# MK30D7 register map
File version: 1.6
Registers are 32-bit, read-write, reset 0x0 unless marked. A register's access mark holds for its fields unless they carry their own. Offsets are from the block's base; [hi:lo] are bit positions; {n}, {i} and the like mark numbered series; 'fields as' and 'values as' point back to an identical list.

## LCD — Segment Liquid Crystal Display
Base 0x400BE000; register names take the prefix LCD_
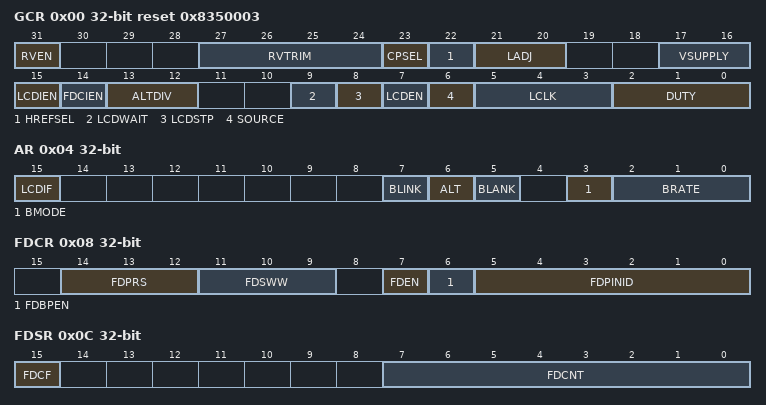
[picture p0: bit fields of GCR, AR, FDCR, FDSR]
0x00 GCR access per field reset 0x8350003 — LCD general control register
  [31] RVEN rw — Regulated voltage enable
    0=Regulated voltage disabled; 1=Regulated voltage enabled
  [27:24] RVTRIM rw — Regulated voltage trim
  [23] CPSEL rw — Charge pump or resistor bias select
    0=LCD charge pump is disabled. Resistor network selected. (The internal 1/3-bias is forced.); 1=LCD charge pump is selected. Resistor network disabled. (The internal 1/3-bias is forced.)
  [22] HREFSEL rw — High reference select
    0=Divide input, VIREG = 1.0 V for 3 V glass; 1=Do not divide the input, VIREG = 1.67 V for 5 V glass
  [21:20] LADJ rw — Load adjust
  [17:16] VSUPPLY rw — Voltage supply control
    0=Drive VLL2 internally from VDD; 1=Drive VLL3 internally from VDD; 3=Drive VLL3 externally from VDD or drive VLL1 internally from VIREG
  [15] LCDIEN rw — LCD frame frequency interrupt enable
    0=No interrupt request is generated by this event; 1=When LCDIF bit is set, this event causes an interrupt request
  [14] FDCIEN rw — LCD fault detection complete interrupt enable
    0=No interrupt request is generated by this event; 1=When a fault is detected and FDCF bit is set, this event causes an interrupt request
  [13:12] ALTDIV rw — LCD alternate clock divider
    0=Divide factor = 1 (No divide); 1=Divide factor = 8
  [9] LCDWAIT rw — LCD driver, charge pump, resistor bias network, and voltage regulator stop while in Wait mode.
    0=Allows the LCD driver, charge pump, resistor bias network, and voltage regulator to continue running during Wait mode; 1=Disables the LCD driver, charge pump, resistor bias network, and voltage regulator when MCU goes into Wait mode
  [8] LCDSTP rw — LCD driver, charge pump, resistor bias network, and voltage regulator while in Stop mode.
    0=Allows the LCD driver, charge pump, resistor bias network, and voltage regulator to continue running during Stop mode; 1=Disables the LCD driver, charge pump, resistor bias network, and voltage regulator when MCU goes into Stop mode
  [7] LCDEN rw — LCD driver enable
    0=All frontplane and backplane pins are disabled. The LCD controller system is also disabled, and all LCD waveform generation clocks are stopped. VLL3 is connected to VDD internally.; 1=LCD controller driver system is enabled, and frontplane and backplane waveforms are generated. All LCD pins, LCD_Pn, enabled using the LCD pin enable register, output an LCD driver waveform.The backplane pins output an LCD driver backplane waveform based on the settings of DUTY[2:0]. Charge pump or resistor bias is enabled.
  [6] SOURCE rw — LCD clock source select
    0=Selects the default clock as the LCD clock source; 1=Selects the alternate clock as the LCD clock source
  [5:3] LCLK rw — LCD clock prescaler
  [2:0] DUTY rw — LCD duty select
    0=Use 1 BP (1/1 duty cycle); 1=Use 2 BP (1/2 duty cycle); 2=Use 3 BP (1/3 duty cycle); 3=Use 4 BP (1/4 duty cycle). (Default); {v}=Use {v+1} BP (1/{v+1} duty cycle) (v=4..7)
0x04 AR access per field — LCD auxiliary register
  [15] LCDIF rw — LCD frame frequency interrupt flag
    0=Frame frequency interrupt condition has not occurred; 1=The start of LCD controller frame has occurred
  [7] BLINK rw — Blink command
    0=Disables blinking; 1=Starts blinking at blinking frequency specified by LCD blink rate calculation
  [6] ALT rw — Alternate display mode
    0=Normal display mode; 1=Alternate display mode
  [5] BLANK rw — Blank display mode
    0=Normal or alternate display mode; 1=Blank display mode
  [3] BMODE rw — Blink mode
    0=Display blank during the blink period; 1=Display alternate display during blink period (Ignored if duty is 5 or greater)
  [2:0] BRATE rw — Blink-rate configuration
0x08 FDCR access per field — LCD fault detect control register
  [14:12] FDPRS rw — Fault detect clock prescaler
    0=1/1 bus clock; 1=1/2 bus clock
  [11:9] FDSWW rw — Fault detect sample window width
    0=Sample window width is 4 sample clock cycles; 1=Sample window width is 8 sample clock cycles
  [7] FDEN rw — Fault detect enable
    0=Disable fault detection; 1=Enable fault detection
  [6] FDBPEN rw — Fault detect backplane enable
    0=Type of the selected pin under fault detect test is frontplane; 1=Type of the selected pin under fault detect test is backplane
  [5:0] FDPINID rw — Fault detect pin ID
    0=Fault detection for LCD_P0 pin; 1=Fault detection for LCD_P1 pin
0x0C FDSR access per field — LCD fault detect status register
  [15] FDCF rw — Fault detection complete flag
    0=Fault detection is not completed; 1=Fault detection is completed
  [7:0] FDCNT ro — Fault detect counter
    0=No "one" samples; 1=1 "one" samples
0x10 PEN{x} (x=L,H; step 0x4) — LCD pin enable register
  [31:0] PEN — LCD pin enable
    0=LCD operation disabled on LCD_Pn; 1=LCD operation enabled on LCD_Pn
0x18 BPEN{x} (x=L,H; step 0x4) — LCD backplane enable register
  [31:0] BPEN — Backplane enable
    0=Frontplane operation enabled on LCD_Pn; 1=Backplane operation enabled on LCD_Pn
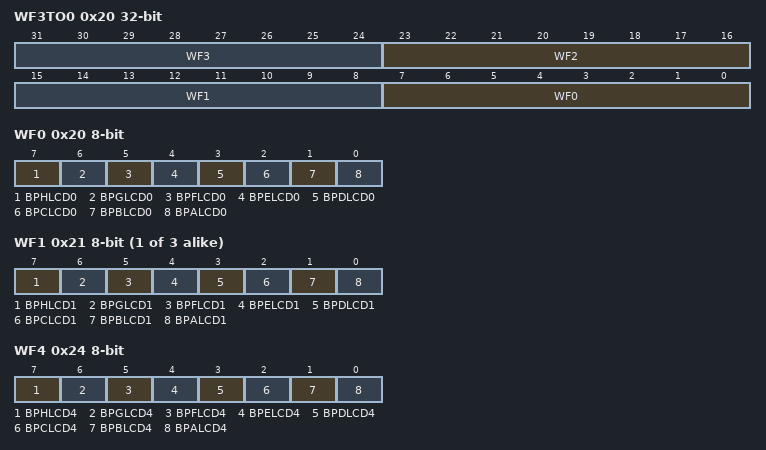
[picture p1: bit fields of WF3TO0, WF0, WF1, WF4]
0x20 WF3TO0 (LCD view) — LCD waveform register
  [8n+7:8n] WF{n} (n=0..3)
0x20 WF0 8-bit reset not defined (LCD view) — LCD Waveform Register 0.
  [7] BPHLCD0
    0=LCD segment off or LCD backplane inactive for phase H; 1=LCD segment on or LCD backplane active for phase H
  [6] BPGLCD0
    0=LCD segment off or LCD backplane inactive for phase G; 1=LCD segment on or LCD backplane active for phase G
  [5] BPFLCD0
    0=LCD segment off or LCD backplane inactive for phase F; 1=LCD segment on or LCD backplane active for phase F
  [4] BPELCD0
    0=LCD segment off or LCD backplane inactive for phase E; 1=LCD segment on or LCD backplane active for phase E
  [3] BPDLCD0
    0=LCD segment off or LCD backplane inactive for phase D; 1=LCD segment on or LCD backplane active for phase D
  [2] BPCLCD0
    0=LCD segment off or LCD backplane inactive for phase C; 1=LCD segment on or LCD backplane active for phase C
  [1] BPBLCD0
    0=LCD segment off or LCD backplane inactive for phase B; 1=LCD segment on or LCD backplane active for phase B
  [0] BPALCD0
    0=LCD segment off or LCD backplane inactive for phase A; 1=LCD segment on or LCD backplane active for phase A
{0x20+i} WF{i} 8-bit reset not defined (i=1..3) — LCD Waveform Register {i}.
  [7] BPHLCD{i}
    values as WF0.BPHLCD0
  [6] BPGLCD{i}
    values as WF0.BPGLCD0
  [5] BPFLCD{i}
    values as WF0.BPFLCD0
  [4] BPELCD{i}
    values as WF0.BPELCD0
  [3] BPDLCD{i}
    values as WF0.BPDLCD0
  [2] BPCLCD{i}
    values as WF0.BPCLCD0
  [1] BPBLCD{i}
    values as WF0.BPBLCD0
  [0] BPALCD{i}
    values as WF0.BPALCD0
0x24 WF4 8-bit reset not defined (LCD view) — LCD Waveform Register 4.
  [7] BPHLCD4
    values as WF0.BPHLCD0
  [6] BPGLCD4
    values as WF0.BPGLCD0
  [5] BPFLCD4
    values as WF0.BPFLCD0
  [4] BPELCD4
    values as WF0.BPELCD0
  [3] BPDLCD4
    values as WF0.BPDLCD0
  [2] BPCLCD4
    values as WF0.BPCLCD0
  [1] BPBLCD4
    values as WF0.BPBLCD0
  [0] BPALCD4
    values as WF0.BPALCD0
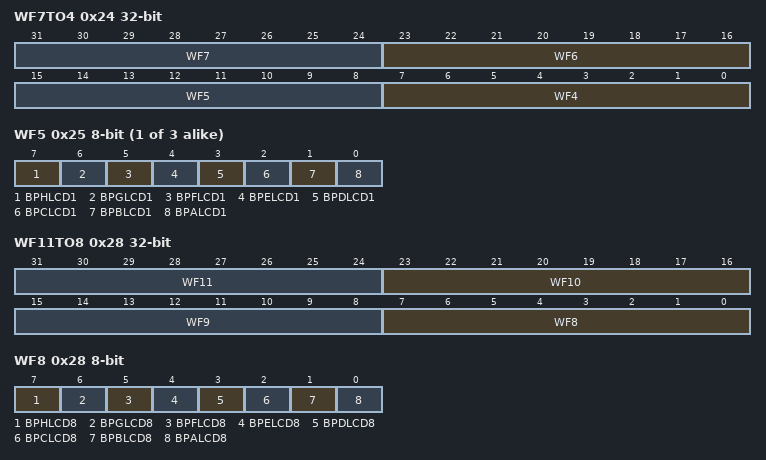
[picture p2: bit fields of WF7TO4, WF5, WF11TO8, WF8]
0x24 WF7TO4 (LCD view) — LCD waveform register
  [8n-25:8n-32] WF{n} (n=4..7)
{0x20+i} WF{i} 8-bit reset not defined (i=5..7) — LCD Waveform Register {i}.
  fields as WF1
0x28 WF11TO8 (LCD view) — LCD waveform register
  [8n-57:8n-64] WF{n} (n=8..11)
0x28 WF8 8-bit reset not defined (LCD view) — LCD Waveform Register 8.
  [7] BPHLCD8
    values as WF0.BPHLCD0
  [6] BPGLCD8
    values as WF0.BPGLCD0
  [5] BPFLCD8
    values as WF0.BPFLCD0
  [4] BPELCD8
    values as WF0.BPELCD0
  [3] BPDLCD8
    values as WF0.BPDLCD0
  [2] BPCLCD8
    values as WF0.BPCLCD0
  [1] BPBLCD8
    values as WF0.BPBLCD0
  [0] BPALCD8
    values as WF0.BPALCD0
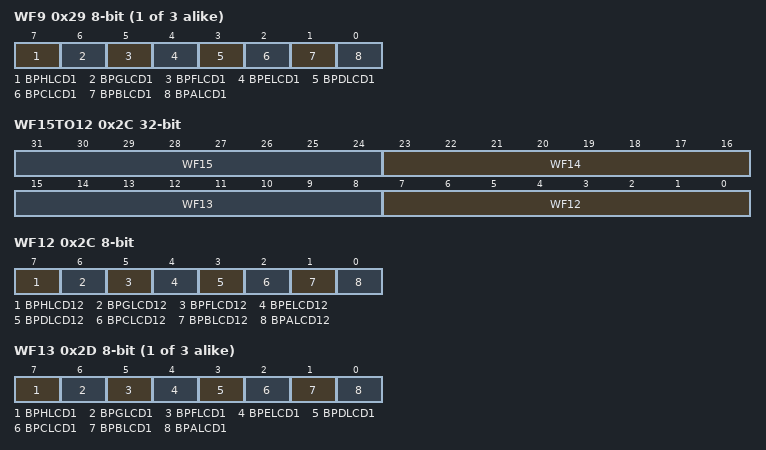
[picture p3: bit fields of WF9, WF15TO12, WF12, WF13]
{0x20+i} WF{i} 8-bit reset not defined (i=9..11) — LCD Waveform Register {i}.
  fields as WF1
0x2C WF15TO12 (LCD view) — LCD waveform register
  [8n-89:8n-96] WF{n} (n=12..15)
0x2C WF12 8-bit reset not defined (LCD view) — LCD Waveform Register 12.
  [7] BPHLCD12
    values as WF0.BPHLCD0
  [6] BPGLCD12
    values as WF0.BPGLCD0
  [5] BPFLCD12
    values as WF0.BPFLCD0
  [4] BPELCD12
    values as WF0.BPELCD0
  [3] BPDLCD12
    values as WF0.BPDLCD0
  [2] BPCLCD12
    values as WF0.BPCLCD0
  [1] BPBLCD12
    values as WF0.BPBLCD0
  [0] BPALCD12
    values as WF0.BPALCD0
{0x20+i} WF{i} 8-bit reset not defined (i=13..15) — LCD Waveform Register {i}.
  fields as WF1
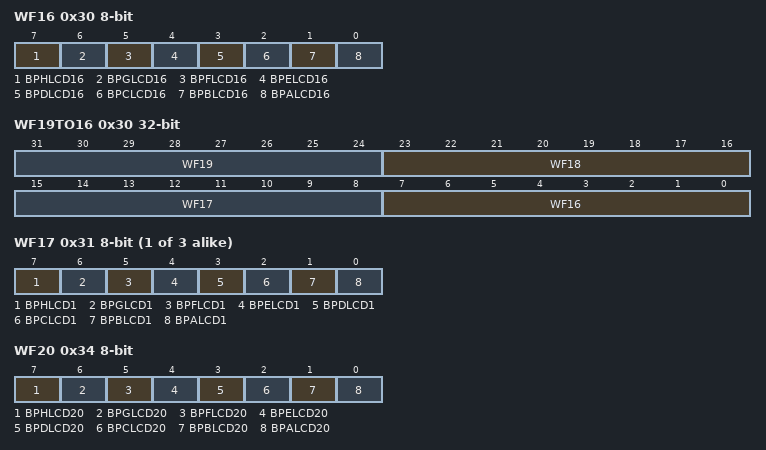
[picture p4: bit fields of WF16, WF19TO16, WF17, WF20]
0x30 WF16 8-bit reset not defined (LCD view) — LCD Waveform Register 16.
  [7] BPHLCD16
    values as WF0.BPHLCD0
  [6] BPGLCD16
    values as WF0.BPGLCD0
  [5] BPFLCD16
    values as WF0.BPFLCD0
  [4] BPELCD16
    values as WF0.BPELCD0
  [3] BPDLCD16
    values as WF0.BPDLCD0
  [2] BPCLCD16
    values as WF0.BPCLCD0
  [1] BPBLCD16
    values as WF0.BPBLCD0
  [0] BPALCD16
    values as WF0.BPALCD0
0x30 WF19TO16 (LCD view) — LCD waveform register
  [8n-121:8n-128] WF{n} (n=16..19)
{0x20+i} WF{i} 8-bit reset not defined (i=17..19) — LCD Waveform Register {i}.
  fields as WF1
0x34 WF20 8-bit reset not defined (LCD view) — LCD Waveform Register 20.
  [7] BPHLCD20
    values as WF0.BPHLCD0
  [6] BPGLCD20
    values as WF0.BPGLCD0
  [5] BPFLCD20
    values as WF0.BPFLCD0
  [4] BPELCD20
    values as WF0.BPELCD0
  [3] BPDLCD20
    values as WF0.BPDLCD0
  [2] BPCLCD20
    values as WF0.BPCLCD0
  [1] BPBLCD20
    values as WF0.BPBLCD0
  [0] BPALCD20
    values as WF0.BPALCD0
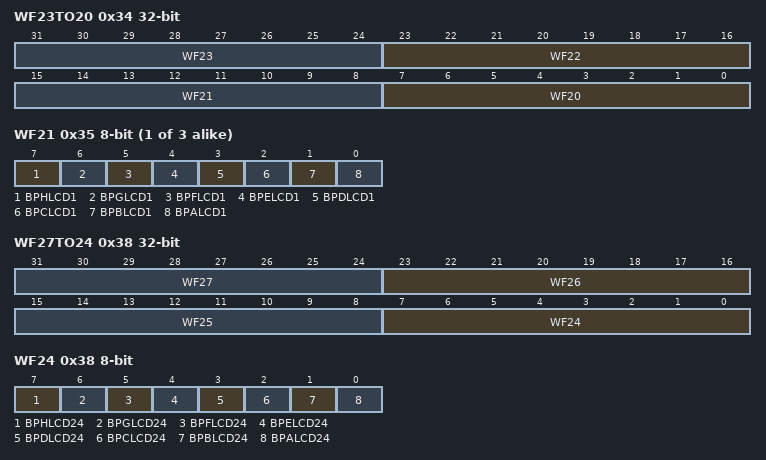
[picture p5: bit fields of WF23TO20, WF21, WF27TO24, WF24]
0x34 WF23TO20 (LCD view) — LCD waveform register
  [8n-153:8n-160] WF{n} (n=20..23)
{0x20+i} WF{i} 8-bit reset not defined (i=21..23) — LCD Waveform Register {i}.
  fields as WF1
0x38 WF27TO24 (LCD view) — LCD waveform register
  [8n-185:8n-192] WF{n} (n=24..27)
0x38 WF24 8-bit reset not defined (LCD view) — LCD Waveform Register 24.
  [7] BPHLCD24
    values as WF0.BPHLCD0
  [6] BPGLCD24
    values as WF0.BPGLCD0
  [5] BPFLCD24
    values as WF0.BPFLCD0
  [4] BPELCD24
    values as WF0.BPELCD0
  [3] BPDLCD24
    values as WF0.BPDLCD0
  [2] BPCLCD24
    values as WF0.BPCLCD0
  [1] BPBLCD24
    values as WF0.BPBLCD0
  [0] BPALCD24
    values as WF0.BPALCD0
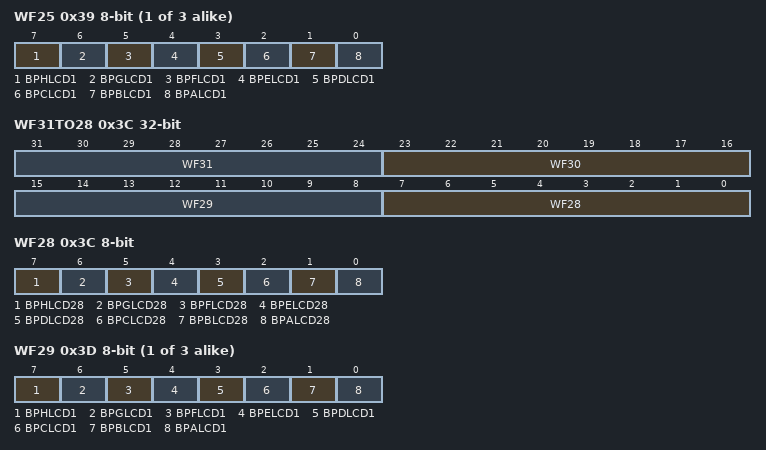
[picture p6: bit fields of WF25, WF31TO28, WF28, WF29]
{0x20+i} WF{i} 8-bit reset not defined (i=25..27) — LCD Waveform Register {i}.
  fields as WF1
0x3C WF31TO28 (LCD view) — LCD waveform register
  [8n-217:8n-224] WF{n} (n=28..31)
0x3C WF28 8-bit reset not defined (LCD view) — LCD Waveform Register 28.
  [7] BPHLCD28
    values as WF0.BPHLCD0
  [6] BPGLCD28
    values as WF0.BPGLCD0
  [5] BPFLCD28
    values as WF0.BPFLCD0
  [4] BPELCD28
    values as WF0.BPELCD0
  [3] BPDLCD28
    values as WF0.BPDLCD0
  [2] BPCLCD28
    values as WF0.BPCLCD0
  [1] BPBLCD28
    values as WF0.BPBLCD0
  [0] BPALCD28
    values as WF0.BPALCD0
{0x20+i} WF{i} 8-bit reset not defined (i=29..31) — LCD Waveform Register {i}.
  fields as WF1
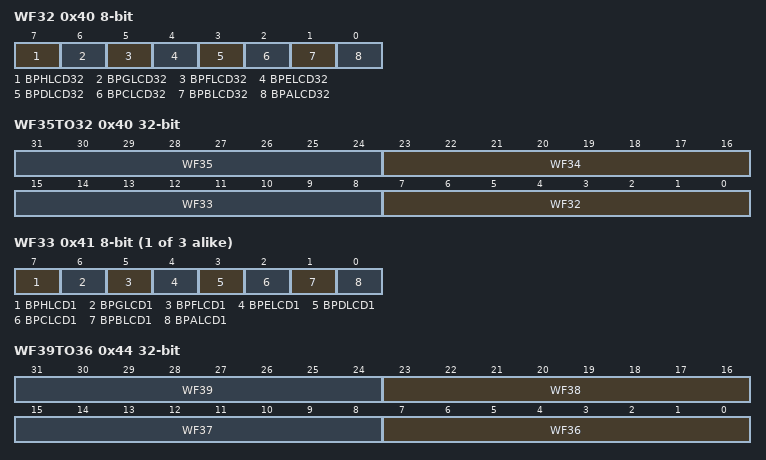
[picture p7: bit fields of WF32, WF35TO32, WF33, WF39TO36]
0x40 WF32 8-bit reset not defined (LCD view) — LCD Waveform Register 32.
  [7] BPHLCD32
    values as WF0.BPHLCD0
  [6] BPGLCD32
    values as WF0.BPGLCD0
  [5] BPFLCD32
    values as WF0.BPFLCD0
  [4] BPELCD32
    values as WF0.BPELCD0
  [3] BPDLCD32
    values as WF0.BPDLCD0
  [2] BPCLCD32
    values as WF0.BPCLCD0
  [1] BPBLCD32
    values as WF0.BPBLCD0
  [0] BPALCD32
    values as WF0.BPALCD0
0x40 WF35TO32 (LCD view) — LCD waveform register
  [8n-249:8n-256] WF{n} (n=32..35)
{0x20+i} WF{i} 8-bit reset not defined (i=33..35) — LCD Waveform Register {i}.
  fields as WF1
0x44 WF39TO36 (LCD view) — LCD waveform register
  [8n-281:8n-288] WF{n} (n=36..39)
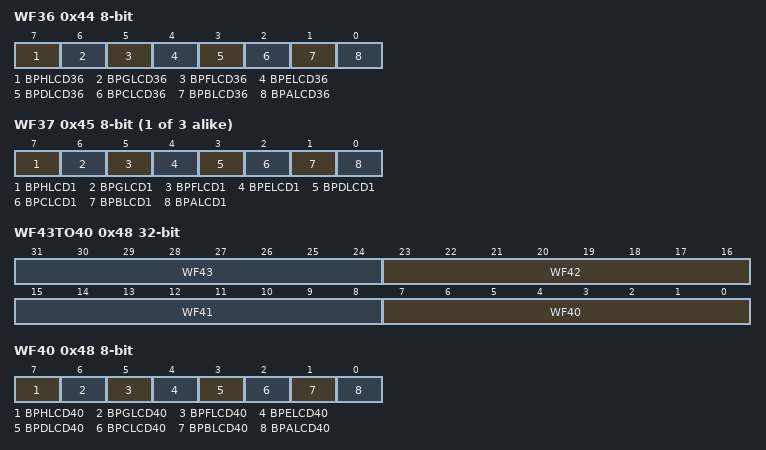
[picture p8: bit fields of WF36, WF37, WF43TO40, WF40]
0x44 WF36 8-bit reset not defined (LCD view) — LCD Waveform Register 36.
  [7] BPHLCD36
    values as WF0.BPHLCD0
  [6] BPGLCD36
    values as WF0.BPGLCD0
  [5] BPFLCD36
    values as WF0.BPFLCD0
  [4] BPELCD36
    values as WF0.BPELCD0
  [3] BPDLCD36
    values as WF0.BPDLCD0
  [2] BPCLCD36
    values as WF0.BPCLCD0
  [1] BPBLCD36
    values as WF0.BPBLCD0
  [0] BPALCD36
    values as WF0.BPALCD0
{0x20+i} WF{i} 8-bit reset not defined (i=37..39) — LCD Waveform Register {i}.
  fields as WF1
0x48 WF43TO40 (LCD view) — LCD waveform register
  [8n-313:8n-320] WF{n} (n=40..43)
0x48 WF40 8-bit reset not defined (LCD view) — LCD Waveform Register 40.
  [7] BPHLCD40
    values as WF0.BPHLCD0
  [6] BPGLCD40
    values as WF0.BPGLCD0
  [5] BPFLCD40
    values as WF0.BPFLCD0
  [4] BPELCD40
    values as WF0.BPELCD0
  [3] BPDLCD40
    values as WF0.BPDLCD0
  [2] BPCLCD40
    values as WF0.BPCLCD0
  [1] BPBLCD40
    values as WF0.BPBLCD0
  [0] BPALCD40
    values as WF0.BPALCD0
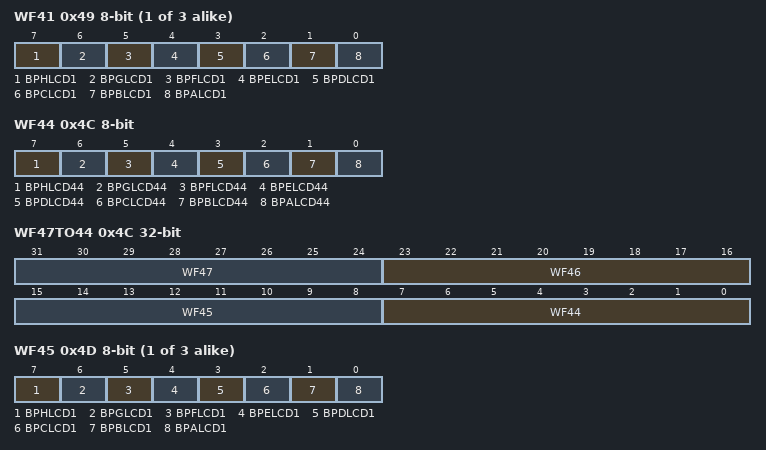
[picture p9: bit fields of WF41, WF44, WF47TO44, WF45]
{0x20+i} WF{i} 8-bit reset not defined (i=41..43) — LCD Waveform Register {i}.
  fields as WF1
0x4C WF44 8-bit reset not defined (LCD view) — LCD Waveform Register 44.
  [7] BPHLCD44
    values as WF0.BPHLCD0
  [6] BPGLCD44
    values as WF0.BPGLCD0
  [5] BPFLCD44
    values as WF0.BPFLCD0
  [4] BPELCD44
    values as WF0.BPELCD0
  [3] BPDLCD44
    values as WF0.BPDLCD0
  [2] BPCLCD44
    values as WF0.BPCLCD0
  [1] BPBLCD44
    values as WF0.BPBLCD0
  [0] BPALCD44
    values as WF0.BPALCD0
0x4C WF47TO44 (LCD view) — LCD waveform register
  [8n-345:8n-352] WF{n} (n=44..47)
{0x20+i} WF{i} 8-bit reset not defined (i=45..47) — LCD Waveform Register {i}.
  fields as WF1
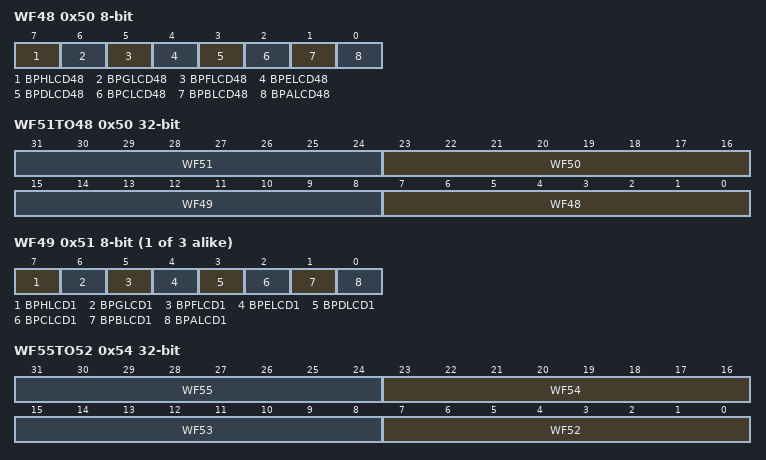
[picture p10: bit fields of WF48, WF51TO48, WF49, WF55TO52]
0x50 WF48 8-bit reset not defined (LCD view) — LCD Waveform Register 48.
  [7] BPHLCD48
    values as WF0.BPHLCD0
  [6] BPGLCD48
    values as WF0.BPGLCD0
  [5] BPFLCD48
    values as WF0.BPFLCD0
  [4] BPELCD48
    values as WF0.BPELCD0
  [3] BPDLCD48
    values as WF0.BPDLCD0
  [2] BPCLCD48
    values as WF0.BPCLCD0
  [1] BPBLCD48
    values as WF0.BPBLCD0
  [0] BPALCD48
    values as WF0.BPALCD0
0x50 WF51TO48 (LCD view) — LCD waveform register
  [8n-377:8n-384] WF{n} (n=48..51)
{0x20+i} WF{i} 8-bit reset not defined (i=49..51) — LCD Waveform Register {i}.
  fields as WF1
0x54 WF55TO52 (LCD view) — LCD waveform register
  [8n-409:8n-416] WF{n} (n=52..55)
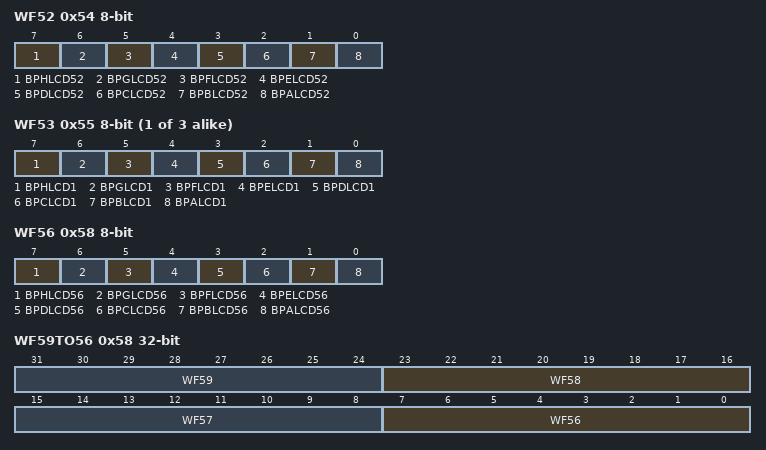
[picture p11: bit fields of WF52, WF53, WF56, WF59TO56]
0x54 WF52 8-bit reset not defined (LCD view) — LCD Waveform Register 52.
  [7] BPHLCD52
    values as WF0.BPHLCD0
  [6] BPGLCD52
    values as WF0.BPGLCD0
  [5] BPFLCD52
    values as WF0.BPFLCD0
  [4] BPELCD52
    values as WF0.BPELCD0
  [3] BPDLCD52
    values as WF0.BPDLCD0
  [2] BPCLCD52
    values as WF0.BPCLCD0
  [1] BPBLCD52
    values as WF0.BPBLCD0
  [0] BPALCD52
    values as WF0.BPALCD0
{0x20+i} WF{i} 8-bit reset not defined (i=53..55) — LCD Waveform Register {i}.
  fields as WF1
0x58 WF56 8-bit reset not defined (LCD view) — LCD Waveform Register 56.
  [7] BPHLCD56
    values as WF0.BPHLCD0
  [6] BPGLCD56
    values as WF0.BPGLCD0
  [5] BPFLCD56
    values as WF0.BPFLCD0
  [4] BPELCD56
    values as WF0.BPELCD0
  [3] BPDLCD56
    values as WF0.BPDLCD0
  [2] BPCLCD56
    values as WF0.BPCLCD0
  [1] BPBLCD56
    values as WF0.BPBLCD0
  [0] BPALCD56
    values as WF0.BPALCD0
0x58 WF59TO56 (LCD view) — LCD waveform register
  [8n-441:8n-448] WF{n} (n=56..59)
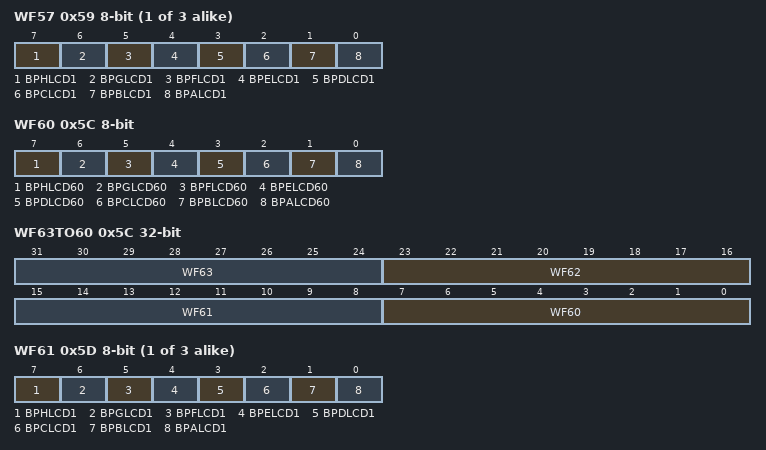
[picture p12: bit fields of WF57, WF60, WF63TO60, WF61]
{0x20+i} WF{i} 8-bit reset not defined (i=57..59) — LCD Waveform Register {i}.
  fields as WF1
0x5C WF60 8-bit reset not defined (LCD view) — LCD Waveform Register 60.
  [7] BPHLCD60
    values as WF0.BPHLCD0
  [6] BPGLCD60
    values as WF0.BPGLCD0
  [5] BPFLCD60
    values as WF0.BPFLCD0
  [4] BPELCD60
    values as WF0.BPELCD0
  [3] BPDLCD60
    values as WF0.BPDLCD0
  [2] BPCLCD60
    values as WF0.BPCLCD0
  [1] BPBLCD60
    values as WF0.BPBLCD0
  [0] BPALCD60
    values as WF0.BPALCD0
0x5C WF63TO60 (LCD view) — LCD waveform register
  [8n-473:8n-480] WF{n} (n=60..63)
{0x20+i} WF{i} 8-bit reset not defined (i=61..63) — LCD Waveform Register {i}.
  fields as WF1
